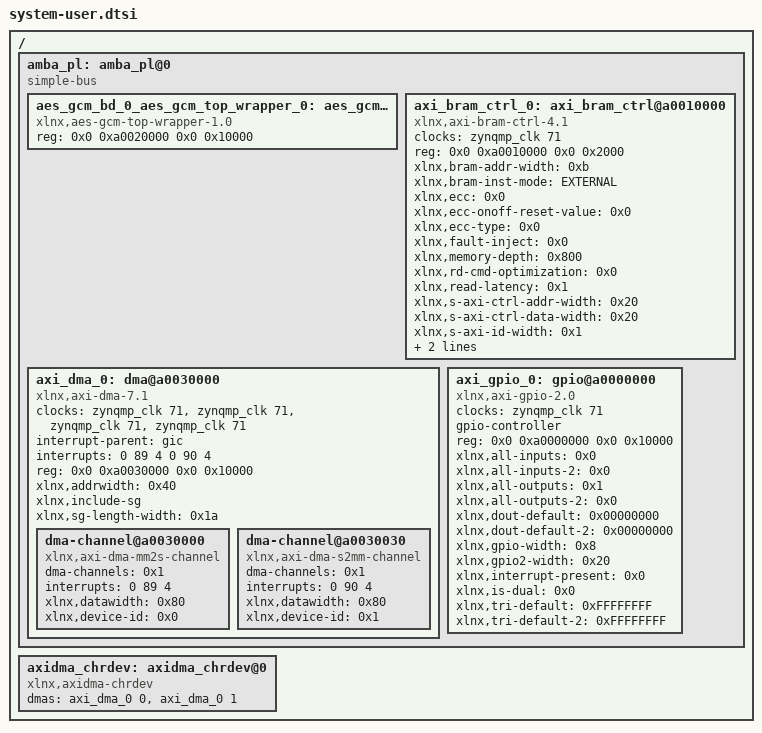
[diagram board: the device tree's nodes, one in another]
/include/ "system-conf.dtsi"
/ {
	amba_pl: amba_pl@0 {
		#address-cells = <2>;
		#size-cells = <2>;
		compatible = "simple-bus";
		ranges ;
		aes_gcm_bd_0_aes_gcm_top_wrapper_0: aes_gcm_top_wrapper@a0020000 {
			compatible = "xlnx,aes-gcm-top-wrapper-1.0";
			reg = <0x0 0xa0020000 0x0 0x10000>;
		};
		axi_bram_ctrl_0: axi_bram_ctrl@a0010000 {
			clock-names = "s_axi_aclk";
			clocks = <&zynqmp_clk 71>;
			compatible = "xlnx,axi-bram-ctrl-4.1";
			reg = <0x0 0xa0010000 0x0 0x2000>;
			xlnx,bram-addr-width = <0xb>;
			xlnx,bram-inst-mode = "EXTERNAL";
			xlnx,ecc = <0x0>;
			xlnx,ecc-onoff-reset-value = <0x0>;
			xlnx,ecc-type = <0x0>;
			xlnx,fault-inject = <0x0>;
			xlnx,memory-depth = <0x800>;
			xlnx,rd-cmd-optimization = <0x0>;
			xlnx,read-latency = <0x1>;
			xlnx,s-axi-ctrl-addr-width = <0x20>;
			xlnx,s-axi-ctrl-data-width = <0x20>;
			xlnx,s-axi-id-width = <0x1>;
			xlnx,s-axi-supports-narrow-burst = <0x1>;
			xlnx,single-port-bram = <0x0>;
		};
		axi_dma_0: dma@a0030000 {
			#dma-cells = <1>;
			clock-names = "s_axi_lite_aclk", "m_axi_sg_aclk", "m_axi_mm2s_aclk", "m_axi_s2mm_aclk";
			clocks = <&zynqmp_clk 71>, <&zynqmp_clk 71>, <&zynqmp_clk 71>, <&zynqmp_clk 71>;
			compatible = "xlnx,axi-dma-7.1", "xlnx,axi-dma-1.00.a";
			interrupt-names = "mm2s_introut", "s2mm_introut";
			interrupt-parent = <&gic>;
			interrupts = <0 89 4 0 90 4>;
			reg = <0x0 0xa0030000 0x0 0x10000>;
			xlnx,addrwidth = <0x40>;
			xlnx,include-sg ;
			xlnx,sg-length-width = <0x1a>;
			dma-channel@a0030000 {
				compatible = "xlnx,axi-dma-mm2s-channel";
				dma-channels = <0x1>;
				interrupts = <0 89 4>;
				xlnx,datawidth = <0x80>;
				xlnx,device-id = <0x0>;
			};
			dma-channel@a0030030 {
				compatible = "xlnx,axi-dma-s2mm-channel";
				dma-channels = <0x1>;
				interrupts = <0 90 4>;
				xlnx,datawidth = <0x80>;
				xlnx,device-id = <0x1>;
			};
		};
		axi_gpio_0: gpio@a0000000 {
			#gpio-cells = <3>;
			clock-names = "s_axi_aclk";
			clocks = <&zynqmp_clk 71>;
			compatible = "xlnx,axi-gpio-2.0", "xlnx,xps-gpio-1.00.a";
			gpio-controller ;
			reg = <0x0 0xa0000000 0x0 0x10000>;
			xlnx,all-inputs = <0x0>;
			xlnx,all-inputs-2 = <0x0>;
			xlnx,all-outputs = <0x1>;
			xlnx,all-outputs-2 = <0x0>;
			xlnx,dout-default = <0x00000000>;
			xlnx,dout-default-2 = <0x00000000>;
			xlnx,gpio-width = <0x8>;
			xlnx,gpio2-width = <0x20>;
			xlnx,interrupt-present = <0x0>;
			xlnx,is-dual = <0x0>;
			xlnx,tri-default = <0xFFFFFFFF>;
			xlnx,tri-default-2 = <0xFFFFFFFF>;
		};
	};
	axidma_chrdev: axidma_chrdev@0 {
		compatible = "xlnx,axidma-chrdev";
		dmas = <&axi_dma_0 0 &axi_dma_0 1>;
		dma-names = "tx_channel", "rx_channel";
	};
	/* 
	 * dma_proxy {  
	 * 	compatible ="xlnx,dma_proxy";
	 * 	dmas = <&axi_dma_0 0 &axi_dma_0 1>;
	 * 	dma-names = "dma_proxy_tx", "dma_proxy_rx";  
	 * 	dma-coherent;
	 * };
         */
};

